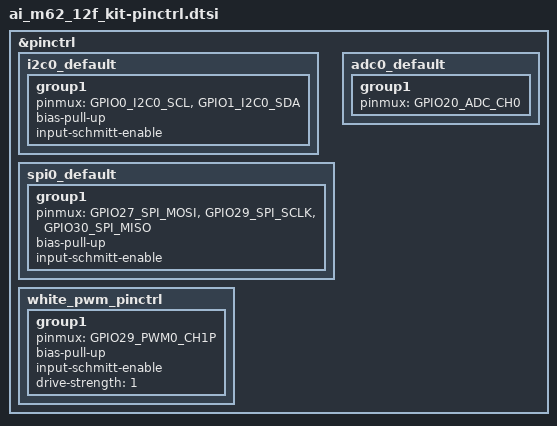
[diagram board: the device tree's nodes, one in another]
/*
 * Copyright (c) 2024-2026 MASSDRIVER EI (massdriver.space)
 *
 * SPDX-License-Identifier: Apache-2.0
 */

&pinctrl {
	i2c0_default: i2c0_default {
		group1 {
			pinmux = <GPIO0_I2C0_SCL>,
				 <GPIO1_I2C0_SDA>;
			bias-pull-up;
			input-schmitt-enable;
		};
	};

	spi0_default: spi0_default {
		group1 {
			pinmux = <GPIO27_SPI_MOSI>,
				 <GPIO29_SPI_SCLK>,
				 <GPIO30_SPI_MISO>;
			bias-pull-up;
			input-schmitt-enable;
		};
	};

	white_pwm_pinctrl: white_pwm_pinctrl {
		group1 {
			pinmux = <GPIO29_PWM0_CH1P>;
			bias-pull-up;
			input-schmitt-enable;
			drive-strength = <1>;
		};
	};

	adc0_default: adc0_default {
		group1 {
			pinmux = <GPIO20_ADC_CH0>;
		};
	};
};
